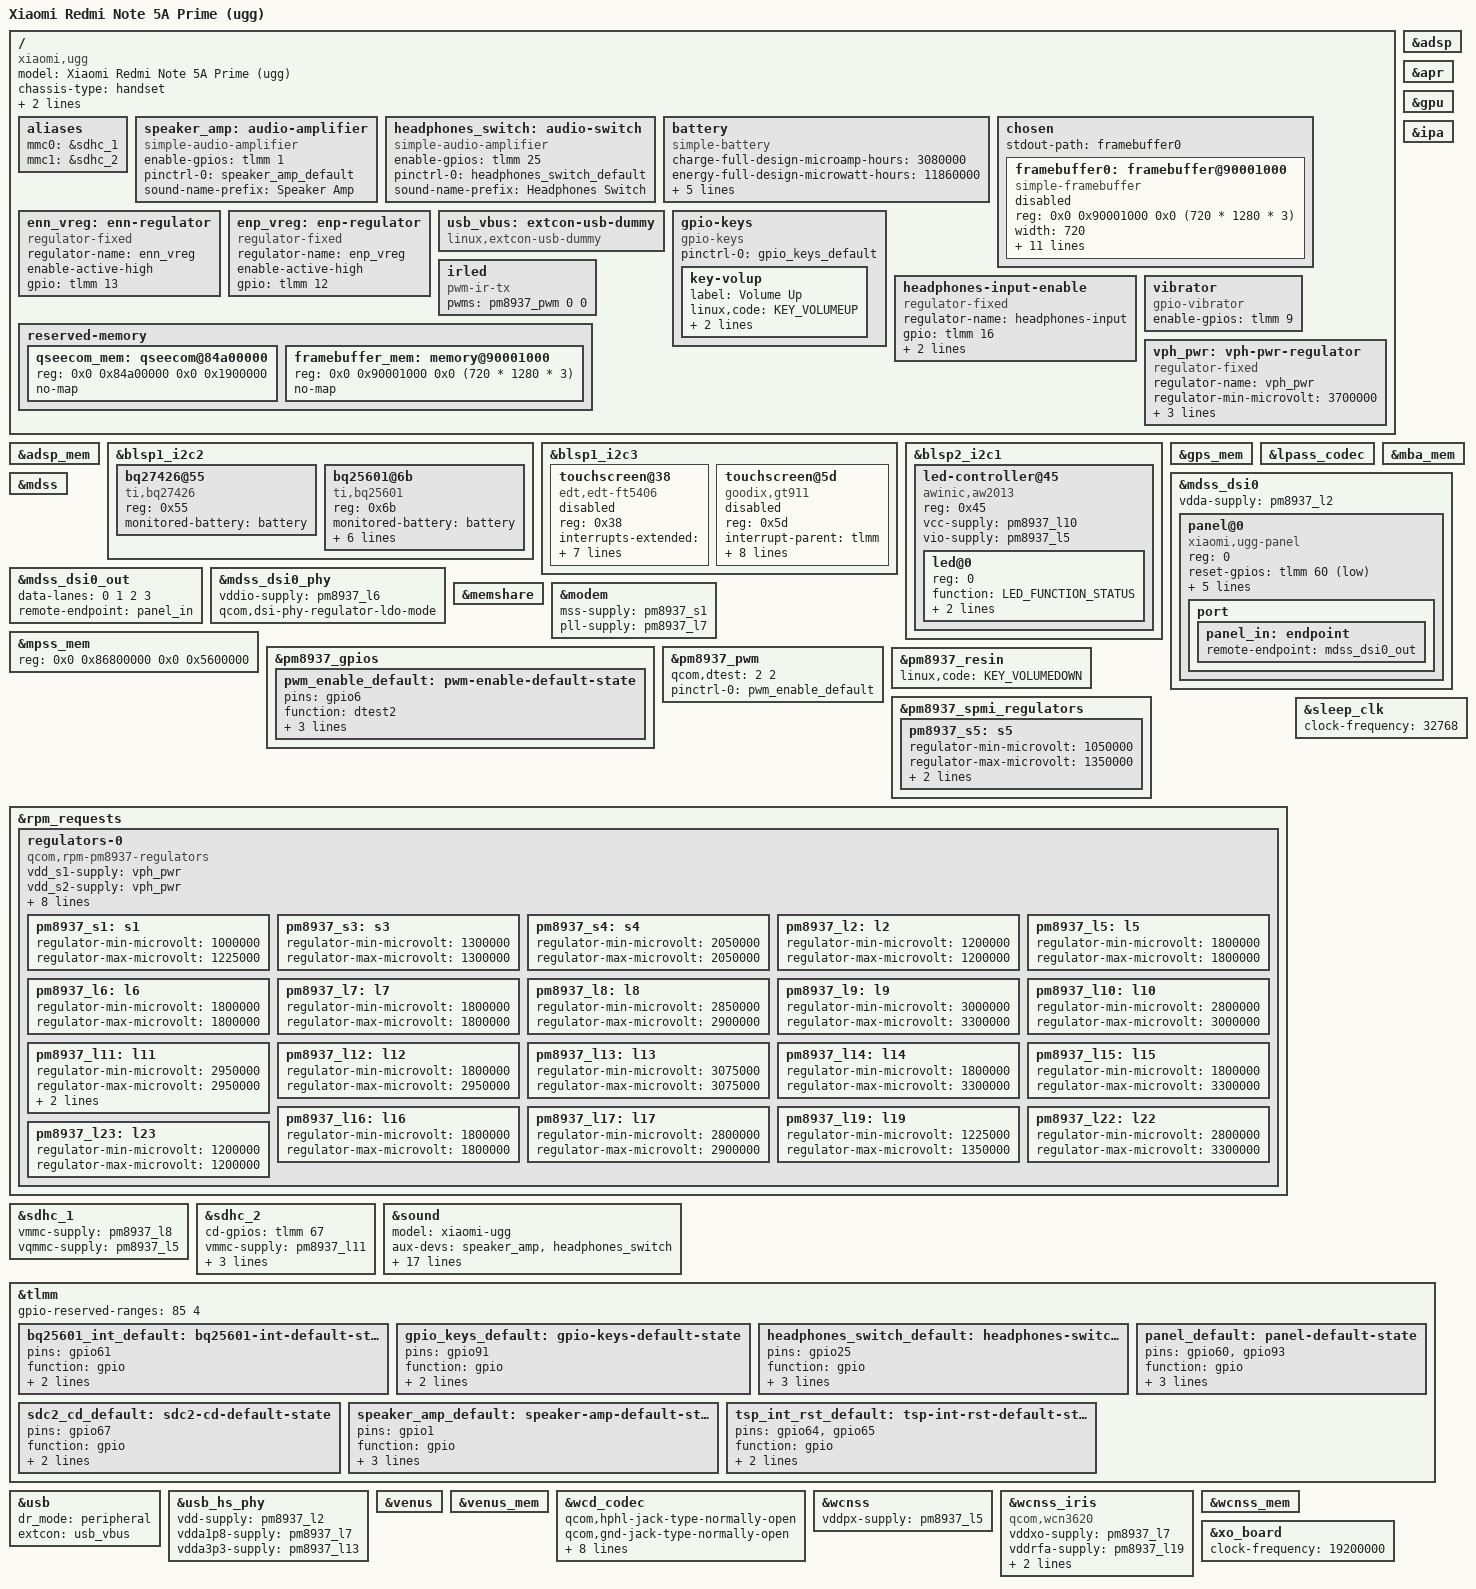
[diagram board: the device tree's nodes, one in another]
// SPDX-License-Identifier: BSD-3-Clause
/*
 * Copyright (c) 2023, Barnabas Czeman
 */

/dts-v1/;

#include <dt-bindings/arm/qcom,ids.h>
#include <dt-bindings/gpio/gpio.h>
#include <dt-bindings/leds/common.h>
#include "msm8940.dtsi"
#include "pm8937.dtsi"
#include "msm8937-qdsp6.dtsi"

/delete-node/ &qseecom_mem;

/ {
	model = "Xiaomi Redmi Note 5A Prime (ugg)";
	compatible = "xiaomi,ugg", "qcom,msm8940";
	chassis-type = "handset";

	qcom,msm-id = <QCOM_ID_MSM8940 0>;
	qcom,board-id = <QCOM_BOARD_ID_MTP 0>;

	aliases {
		mmc0 = &sdhc_1;
		mmc1 = &sdhc_2;
	};

	speaker_amp: audio-amplifier {
		compatible = "simple-audio-amplifier";
		enable-gpios = <&tlmm 1 GPIO_ACTIVE_HIGH>;
		pinctrl-0 = <&speaker_amp_default>;
		pinctrl-names = "default";
		sound-name-prefix = "Speaker Amp";
	};

	headphones_switch: audio-switch {
		compatible = "simple-audio-amplifier";
		enable-gpios = <&tlmm 25 GPIO_ACTIVE_HIGH>;
		pinctrl-0 = <&headphones_switch_default>;
		pinctrl-names = "default";
		sound-name-prefix = "Headphones Switch";
	};

	battery: battery {
		compatible = "simple-battery";
		charge-full-design-microamp-hours = <3080000>;
		energy-full-design-microwatt-hours = <11860000>;
		constant-charge-current-max-microamp = <1000000>;
		constant-charge-voltage-max-microvolt = <4400000>;
		precharge-current-microamp = <120000>;
		charge-term-current-microamp = <120000>;
		voltage-min-design-microvolt = <3400000>;
	};

	chosen {
		#address-cells = <2>;
		#size-cells = <2>;
		ranges;

		stdout-path = "framebuffer0";

		framebuffer0: framebuffer@90001000 {
			compatible = "simple-framebuffer";
			reg = <0x0 0x90001000 0x0 (720 * 1280 * 3)>;
			width = <720>;
			height = <1280>;
			stride = <(720 * 3)>;
			format = "r8g8b8";

			clocks = <&gcc GCC_MDSS_AHB_CLK>,
				 <&gcc GCC_MDSS_AXI_CLK>,
				 <&gcc GCC_MDSS_VSYNC_CLK>,
				 <&gcc GCC_MDSS_MDP_CLK>,
				 <&gcc GCC_MDSS_BYTE0_CLK>,
				 <&gcc GCC_MDSS_PCLK0_CLK>,
				 <&gcc GCC_MDSS_ESC0_CLK>;
			power-domains = <&gcc MDSS_GDSC>;
			status = "disabled";
		};
	};

	enn_vreg: enn-regulator {
		compatible = "regulator-fixed";
		regulator-name = "enn_vreg";
		enable-active-high;
		gpio = <&tlmm 13 GPIO_ACTIVE_HIGH>;
	};

	enp_vreg: enp-regulator {
		compatible = "regulator-fixed";
		regulator-name = "enp_vreg";
		enable-active-high;
		gpio = <&tlmm 12 GPIO_ACTIVE_HIGH>;
	};

	usb_vbus: extcon-usb-dummy {
		compatible = "linux,extcon-usb-dummy";
	};

	gpio-keys {
		compatible = "gpio-keys";

		pinctrl-0 = <&gpio_keys_default>;
		pinctrl-names = "default";

		key-volup {
			label = "Volume Up";
			linux,code = <KEY_VOLUMEUP>;
			gpios = <&tlmm 91 GPIO_ACTIVE_LOW>;
			debounce-interval = <15>;
		};
	};

	headphones-input-enable {
		compatible = "regulator-fixed";
		regulator-name = "headphones-input";
		gpio = <&tlmm 16 GPIO_ACTIVE_HIGH>;
		enable-active-high;
		regulator-always-on;
	};

	irled {
		compatible = "pwm-ir-tx";
		pwms = <&pm8937_pwm 0 0>;
	};

	reserved-memory {
		qseecom_mem: qseecom@84a00000 {
			reg = <0x0 0x84a00000 0x0 0x1900000>;
			no-map;
		};

		framebuffer_mem: memory@90001000 {
			reg = <0x0 0x90001000 0x0 (720 * 1280 * 3)>;
			no-map;
		};
	};

	vibrator {
		compatible = "gpio-vibrator";
		enable-gpios = <&tlmm 9 GPIO_ACTIVE_HIGH>;
	};

	vph_pwr: vph-pwr-regulator {
		compatible = "regulator-fixed";
		regulator-name = "vph_pwr";
		regulator-min-microvolt = <3700000>;
		regulator-max-microvolt = <3700000>;
		regulator-always-on;
		regulator-boot-on;
	};
};

&adsp {
	status = "okay";
};

&adsp_mem {
	status = "okay";
};

&apr {
	status = "okay";
};

&blsp1_i2c2 {
	status = "okay";

	bq27426@55 {
		compatible = "ti,bq27426";
		reg = <0x55>;
		monitored-battery = <&battery>;
	};

	bq25601@6b{
		compatible = "ti,bq25601";
		reg = <0x6b>;
		monitored-battery = <&battery>;

		interrupts-extended = <&tlmm 61 IRQ_TYPE_EDGE_FALLING>;
		pinctrl-0 = <&bq25601_int_default>;
		pinctrl-names = "default";

		input-voltage-limit-microvolt = <4500000>;
		input-current-limit-microamp = <2000000>;

		omit-battery-class;
	};
};

&blsp1_i2c3 {
	status = "okay";

	touchscreen@38 {
		compatible = "edt,edt-ft5406";
		reg = <0x38>;

		interrupts-extended = <&tlmm 65 IRQ_TYPE_EDGE_FALLING>;
		reset-gpios = <&tlmm 64 GPIO_ACTIVE_LOW>;
		vcc-supply = <&pm8937_l10>;
		iovcc-supply = <&pm8937_l5>;

		pinctrl-0 = <&tsp_int_rst_default>;
		pinctrl-names = "default";

		touchscreen-size-x = <720>;
		touchscreen-size-y = <1280>;

		status = "disabled";
	};

	touchscreen@5d {
		compatible = "goodix,gt911";
		reg = <0x5d>;
		interrupt-parent = <&tlmm>;
		interrupts = <65 IRQ_TYPE_EDGE_FALLING>;
		irq-gpios = <&tlmm 65 GPIO_ACTIVE_HIGH>;
		reset-gpios = <&tlmm 64 GPIO_ACTIVE_HIGH>;
		AVDD28-supply = <&pm8937_l10>;
		VDDIO-supply = <&pm8937_l6>;

		pinctrl-0 = <&tsp_int_rst_default>;
		pinctrl-names = "default";

		touchscreen-size-x = <720>;
		touchscreen-size-y = <1280>;

		status = "disabled";
	};
};

&blsp2_i2c1 {
	status = "okay";

	led-controller@45 {
		compatible = "awinic,aw2013";
		reg = <0x45>;
		#address-cells = <1>;
		#size-cells = <0>;

		vcc-supply = <&pm8937_l10>;
		vio-supply = <&pm8937_l5>;

		led@0 {
			reg = <0>;
			function = LED_FUNCTION_STATUS;
			led-max-microamp = <5000>;
			color = <LED_COLOR_ID_WHITE>;
		};
	};
};

&gps_mem {
	status = "okay";
};

&gpu {
	status = "okay";
};

&ipa {
	status = "okay";
};

&lpass_codec{
	status = "okay";
};

&mba_mem {
	status = "okay";
};

&mdss {
	status = "okay";
};

&mdss_dsi0 {
	vdda-supply = <&pm8937_l2>;

	status = "okay";

	panel@0 {
		compatible = "xiaomi,ugg-panel";

		reg = <0>;
		reset-gpios = <&tlmm 60 GPIO_ACTIVE_LOW>;

		vddio-supply = <&pm8937_l6>;
		avee-supply = <&enn_vreg>;
		avdd-supply = <&enp_vreg>;

		backlight-gpios = <&tlmm 93 GPIO_ACTIVE_HIGH>;

		pinctrl-0 = <&panel_default>;
		pinctrl-names = "default";

		port {
			panel_in: endpoint {
				remote-endpoint = <&mdss_dsi0_out>;
			};
		};
	};
};

&mdss_dsi0_out {
	data-lanes = <0 1 2 3>;
	remote-endpoint = <&panel_in>;
};

&mdss_dsi0_phy {
	vddio-supply = <&pm8937_l6>;
	qcom,dsi-phy-regulator-ldo-mode;

	status = "okay";
};

&memshare {
	status = "okay";
};

&modem {
	mss-supply = <&pm8937_s1>;
	pll-supply = <&pm8937_l7>;
	status = "okay";
};

&mpss_mem {
	reg = <0x0 0x86800000 0x0 0x5600000>;
	status = "okay";
};

&pm8937_gpios {
	pwm_enable_default: pwm-enable-default-state {
		pins = "gpio6";
		function = "dtest2";
		output-low;
		bias-pull-down;
		qcom,drive-strength = <2>;
	};
};

&pm8937_pwm {
	qcom,dtest = <2 2>;
	pinctrl-0 = <&pwm_enable_default>;
	pinctrl-names = "default";

	status = "okay";
};

&pm8937_resin {
	linux,code = <KEY_VOLUMEDOWN>;
	status = "okay";
};

&pm8937_spmi_regulators {
	pm8937_s5: s5 {
		regulator-min-microvolt = <1050000>;
		regulator-max-microvolt = <1350000>;
		regulator-always-on;
		regulator-boot-on;
	};
};

&rpm_requests {
	regulators-0 {
		compatible = "qcom,rpm-pm8937-regulators";

		vdd_s1-supply = <&vph_pwr>;
		vdd_s2-supply = <&vph_pwr>;
		vdd_s3-supply = <&vph_pwr>;
		vdd_s4-supply = <&vph_pwr>;

		vdd_l1_l19-supply = <&pm8937_s3>;
		vdd_l2_l23-supply = <&pm8937_s3>;
		vdd_l3-supply = <&pm8937_s3>;
		vdd_l4_l5_l6_l7_l16-supply = <&pm8937_s4>;
		vdd_l8_l11_l12_l17_l22-supply = <&vph_pwr>;
		vdd_l9_l10_l13_l14_l15_l18-supply = <&vph_pwr>;

		pm8937_s1: s1 {
			regulator-min-microvolt = <1000000>;
			regulator-max-microvolt = <1225000>;
		};

		pm8937_s3: s3 {
			regulator-min-microvolt = <1300000>;
			regulator-max-microvolt = <1300000>;
		};

		pm8937_s4: s4 {
			regulator-min-microvolt = <2050000>;
			regulator-max-microvolt = <2050000>;
		};

		pm8937_l2: l2 {
			regulator-min-microvolt = <1200000>;
			regulator-max-microvolt = <1200000>;
		};

		pm8937_l5: l5 {
			regulator-min-microvolt = <1800000>;
			regulator-max-microvolt = <1800000>;
		};

		pm8937_l6: l6 {
			regulator-min-microvolt = <1800000>;
			regulator-max-microvolt = <1800000>;
		};

		pm8937_l7: l7 {
			regulator-min-microvolt = <1800000>;
			regulator-max-microvolt = <1800000>;
		};

		pm8937_l8: l8 {
			regulator-min-microvolt = <2850000>;
			regulator-max-microvolt = <2900000>;
		};

		pm8937_l9: l9 {
			regulator-min-microvolt = <3000000>;
			regulator-max-microvolt = <3300000>;
		};

		pm8937_l10: l10 {
			regulator-min-microvolt = <2800000>;
			regulator-max-microvolt = <3000000>;
		};

		pm8937_l11: l11 {
			regulator-min-microvolt = <2950000>;
			regulator-max-microvolt = <2950000>;
			regulator-allow-set-load;
			regulator-system-load = <200000>;
		};

		pm8937_l12: l12 {
			regulator-min-microvolt = <1800000>;
			regulator-max-microvolt = <2950000>;
		};

		pm8937_l13: l13 {
			regulator-min-microvolt = <3075000>;
			regulator-max-microvolt = <3075000>;
		};

		pm8937_l14: l14 {
			regulator-min-microvolt = <1800000>;
			regulator-max-microvolt = <3300000>;
		};

		pm8937_l15: l15 {
			regulator-min-microvolt = <1800000>;
			regulator-max-microvolt = <3300000>;
		};

		pm8937_l16: l16 {
			regulator-min-microvolt = <1800000>;
			regulator-max-microvolt = <1800000>;
		};

		pm8937_l17: l17 {
			regulator-min-microvolt = <2800000>;
			regulator-max-microvolt = <2900000>;
		};

		pm8937_l19: l19 {
			regulator-min-microvolt = <1225000>;
			regulator-max-microvolt = <1350000>;
		};

		pm8937_l22: l22 {
			regulator-min-microvolt = <2800000>;
			regulator-max-microvolt = <3300000>;
		};

		pm8937_l23: l23 {
			regulator-min-microvolt = <1200000>;
			regulator-max-microvolt = <1200000>;
		};
	};
};

&sdhc_1 {
	vmmc-supply = <&pm8937_l8>;
	vqmmc-supply = <&pm8937_l5>;
	status = "okay";
};

&sdhc_2 {
	cd-gpios = <&tlmm 67 GPIO_ACTIVE_HIGH>;
	vmmc-supply = <&pm8937_l11>;
	vqmmc-supply = <&pm8937_l12>;
	pinctrl-0 = <&sdc2_default &sdc2_cd_default>;
	pinctrl-1 = <&sdc2_sleep &sdc2_cd_default>;
	pinctrl-names = "default", "sleep";
	status = "okay";
};

&sleep_clk {
	clock-frequency = <32768>;
};

&sound {
	model = "xiaomi-ugg";

	aux-devs = <&speaker_amp>, <&headphones_switch>;
	widgets =
		"Speaker", "Speaker",
		"Headphone", "Headphones";
	pin-switches = "Speaker", "Headphones";
	audio-routing =
		"Speaker", "Speaker Amp OUTL",
		"Speaker", "Speaker Amp OUTR",
		"Speaker Amp INL", "HPHL",
		"Speaker Amp INR", "HPHL",
		"Headphones", "Headphones Switch OUTL",
		"Headphones", "Headphones Switch OUTR",
		"Headphones Switch INL", "HPHL",
		"Headphones Switch INR", "HPHR",
		"AMIC1", "MIC BIAS External1",
		"AMIC2", "MIC BIAS External2",
		"AMIC3", "MIC BIAS External1",
		"MM_DL1", "MultiMedia1 Playback",
		"MM_DL3", "MultiMedia3 Playback",
		"MM_DL4", "MultiMedia4 Playback",
		"MultiMedia2 Capture", "MM_UL2";

	status = "okay";
};

&tlmm {
	gpio-reserved-ranges = <85 4>;

	bq25601_int_default: bq25601-int-default-state {
		pins = "gpio61";
		function = "gpio";
		drive-strength = <2>;
		bias-pull-up;
	};

	gpio_keys_default: gpio-keys-default-state {
		pins = "gpio91";
		function = "gpio";
		drive-strength = <2>;
		bias-pull-up;
	};

	headphones_switch_default: headphones-switch-default-state {
		pins = "gpio25";
		function = "gpio";
		drive-strength = <8>;
		bias-pull-up;
		output-high;
	};

	panel_default: panel-default-state {
		pins = "gpio60", "gpio93";
		function = "gpio";
		drive-strength = <8>;
		bias-disable;
		output-high;
	};

	sdc2_cd_default: sdc2-cd-default-state {
		pins = "gpio67";
		function = "gpio";
		drive-strength = <2>;
		bias-disable;
	};

	speaker_amp_default: speaker-amp-default-state {
		pins = "gpio1";
		function = "gpio";
		drive-strength = <8>;
		bias-pull-up;
		output-high;
	};

	tsp_int_rst_default: tsp-int-rst-default-state {
		pins = "gpio64", "gpio65";
		function = "gpio";
		drive-strength = <8>;
		bias-pull-up;
	};
};

&usb {
	dr_mode = "peripheral";
	extcon = <&usb_vbus>;
	status = "okay";
};

&usb_hs_phy {
	vdd-supply = <&pm8937_l2>;
	vdda1p8-supply = <&pm8937_l7>;
	vdda3p3-supply = <&pm8937_l13>;
	status = "okay";
};

&venus {
	status = "okay";
};

&venus_mem {
	status = "okay";
};

&wcd_codec {
	qcom,hphl-jack-type-normally-open;
	qcom,gnd-jack-type-normally-open;
	qcom,mbhc-vthreshold-high = <100 200 450 500 500>;
	qcom,mbhc-vthreshold-low = <100 200 450 500 500>;
	qcom,micbias-lvl = <2800>;
	qcom,micbias1-ext-cap;
	qcom,micbias2-ext-cap;

	vdd-cdc-io-supply = <&pm8937_l5>;
	vdd-cdc-tx-rx-cx-supply = <&pm8937_s4>;
	vdd-micbias-supply = <&pm8937_l13>;
	status = "okay";
};

&wcnss {
	vddpx-supply = <&pm8937_l5>;
	status = "okay";
};

&wcnss_iris {
	compatible = "qcom,wcn3620";
	vddxo-supply = <&pm8937_l7>;
	vddrfa-supply = <&pm8937_l19>;
	vddpa-supply = <&pm8937_l9>;
	vdddig-supply = <&pm8937_l5>;
};

&wcnss_mem {
	status = "okay";
};

&xo_board {
	clock-frequency = <19200000>;
};
